CM_ "AUTOGENERATED FILE, DO NOT EDIT";

CM_ "Imported file _subaru_global.dbc starts here";
VERSION ""

NS_ :

BS_:

BU_: XXX X

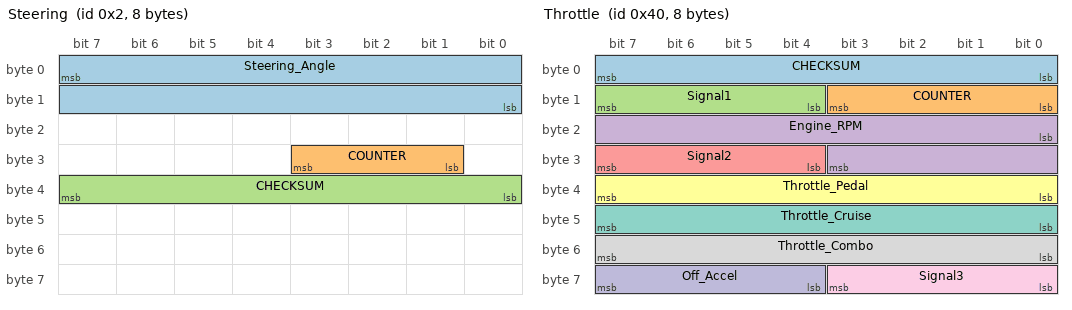
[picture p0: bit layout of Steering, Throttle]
BO_ 2 Steering: 8 XXX
 SG_ Steering_Angle : 7|16@0- (0.1,0) [0|65535] "" XXX
 SG_ COUNTER : 25|3@1+ (1,0) [0|7] "" XXX
 SG_ CHECKSUM : 32|8@1+ (1,0) [0|255] "" XXX

BO_ 64 Throttle: 8 XXX
 SG_ CHECKSUM : 0|8@1+ (1,0) [0|255] "" XXX
 SG_ COUNTER : 8|4@1+ (1,0) [0|15] "" XXX
 SG_ Signal1 : 12|4@1+ (1,0) [0|15] "" XXX
 SG_ Engine_RPM : 16|12@1+ (1,0) [0|4095] "" XXX
 SG_ Signal2 : 28|4@1+ (1,0) [0|15] "" XXX
 SG_ Throttle_Pedal : 32|8@1+ (1,0) [0|255] "" XXX
 SG_ Throttle_Cruise : 40|8@1+ (1,0) [0|255] "" XXX
 SG_ Throttle_Combo : 48|8@1+ (1,0) [0|255] "" XXX
 SG_ Signal3 : 56|4@1+ (1,0) [0|15] "" XXX
 SG_ Off_Accel : 60|4@1+ (1,0) [0|15] "" XXX

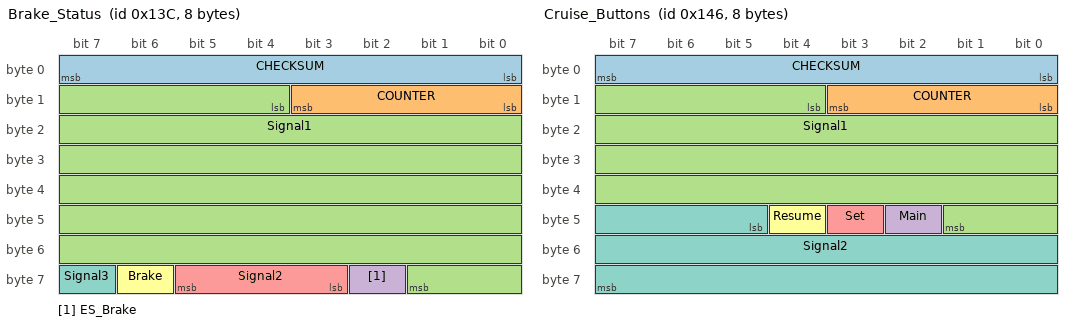
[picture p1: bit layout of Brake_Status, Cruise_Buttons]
BO_ 316 Brake_Status: 8 XXX
 SG_ CHECKSUM : 0|8@1+ (1,0) [0|255] "" XXX
 SG_ COUNTER : 8|4@1+ (1,0) [0|15] "" XXX
 SG_ Signal1 : 12|46@1+ (1,0) [0|1] "" XXX
 SG_ ES_Brake : 58|1@1+ (1,0) [0|1] "" XXX
 SG_ Signal2 : 59|3@1+ (1,0) [0|1] "" XXX
 SG_ Brake : 62|1@1+ (1,0) [0|1] "" XXX
 SG_ Signal3 : 63|1@1+ (1,0) [0|1] "" XXX

BO_ 326 Cruise_Buttons: 8 XXX
 SG_ CHECKSUM : 0|8@1+ (1,0) [0|255] "" XXX
 SG_ COUNTER : 8|4@1+ (1,0) [0|15] "" XXX
 SG_ Signal1 : 12|30@1+ (1,0) [0|1073741823] "" XXX
 SG_ Main : 42|1@1+ (1,0) [0|1] "" XXX
 SG_ Set : 43|1@1+ (1,0) [0|1] "" XXX
 SG_ Resume : 44|1@1+ (1,0) [0|1] "" XXX
 SG_ Signal2 : 45|19@1+ (1,0) [0|524287] "" XXX

BO_ 315 G_Sensor: 8 XXX
 SG_ Lateral : 48|8@1- (-0.1,0) [0|255] "m/s2" XXX
 SG_ Longitudinal : 56|8@1- (-0.1,0) [0|255] "m/s2" XXX

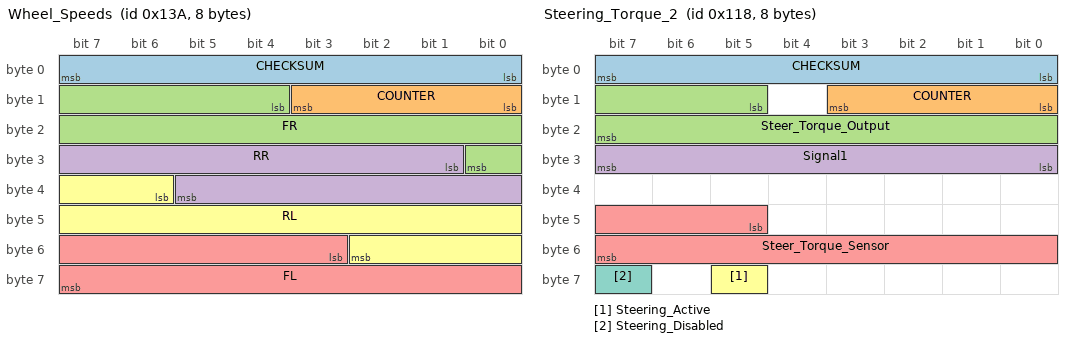
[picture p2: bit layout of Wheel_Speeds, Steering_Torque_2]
BO_ 314 Wheel_Speeds: 8 XXX
 SG_ CHECKSUM : 0|8@1+ (1,0) [0|255] "" XXX
 SG_ COUNTER : 8|4@1+ (1,0) [0|15] "" XXX
 SG_ FR : 12|13@1+ (0.057,0) [0|255] "kph" XXX
 SG_ RR : 25|13@1+ (0.057,0) [0|255] "kph" XXX
 SG_ FL : 51|13@1+ (0.057,0) [0|255] "kph" XXX
 SG_ RL : 38|13@1+ (0.057,0) [0|255] "kph" XXX

BO_ 280 Steering_Torque_2: 8 XXX
 SG_ CHECKSUM : 0|8@1+ (1,0) [0|255] "" XXX
 SG_ COUNTER : 8|4@1+ (1,0) [0|15] "" XXX
 SG_ Steer_Torque_Output : 13|11@1- (-10,0) [0|255] "" XXX
 SG_ Signal1 : 24|8@1+ (1,0) [0|511] "" XXX
 SG_ Steer_Torque_Sensor : 45|11@1- (-1,0) [0|255] "" XXX
 SG_ Steering_Active : 61|1@0+ (1,0) [0|1] "" XXX
 SG_ Steering_Disabled : 63|1@1+ (1,0) [0|1] "" XXX

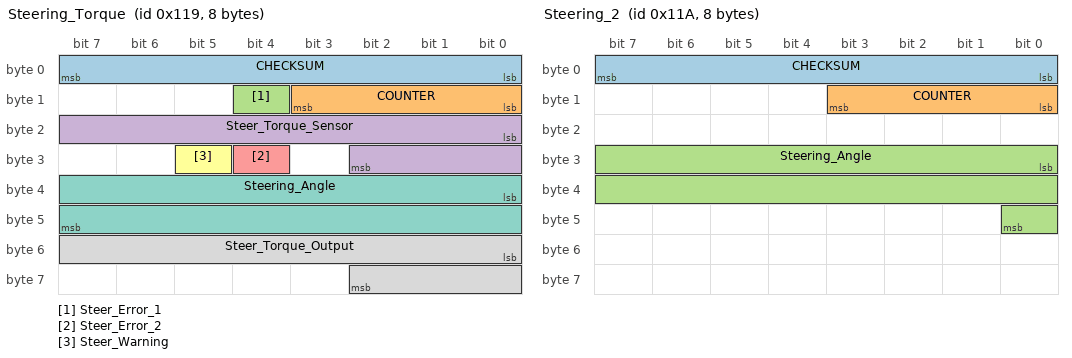
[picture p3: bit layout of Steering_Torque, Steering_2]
BO_ 281 Steering_Torque: 8 XXX
 SG_ CHECKSUM : 0|8@1+ (1,0) [0|255] "" XXX
 SG_ COUNTER : 8|4@1+ (1,0) [0|15] "" XXX
 SG_ Steer_Error_1 : 12|1@0+ (1,0) [0|1] "" XXX
 SG_ Steer_Torque_Sensor : 16|11@1- (-1,0) [-1000|1000] "" XXX
 SG_ Steer_Error_2 : 28|1@1+ (1,0) [0|1] "" XXX
 SG_ Steer_Warning : 29|1@1+ (1,0) [0|1] "" XXX
 SG_ Steering_Angle : 32|16@1- (-0.0217,0) [-600|600] "" X
 SG_ Steer_Torque_Output : 48|11@1- (-10,0) [-1000|1000] "" XXX

BO_ 282 Steering_2: 8 XXX
 SG_ CHECKSUM : 0|8@1+ (1,0) [0|1] "" XXX
 SG_ COUNTER : 8|4@1+ (1,0) [0|1] "" XXX
 SG_ Steering_Angle : 24|17@1- (-0.01,0) [0|1] "" XXX

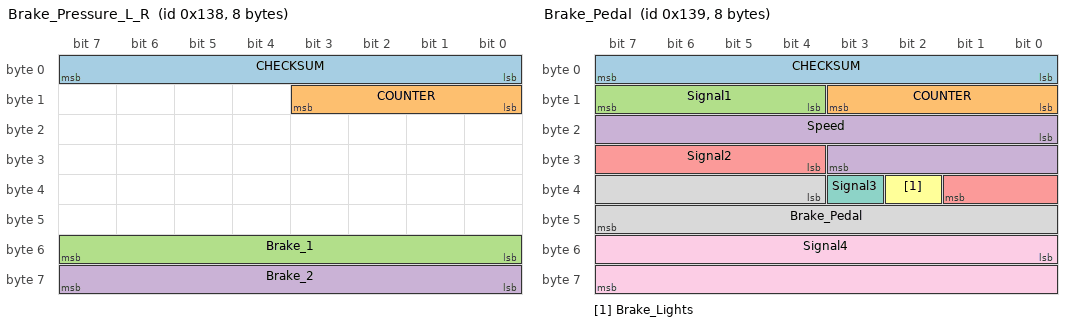
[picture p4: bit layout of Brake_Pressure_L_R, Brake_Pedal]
BO_ 312 Brake_Pressure_L_R: 8 XXX
 SG_ CHECKSUM : 0|8@1+ (1,0) [0|255] "" XXX
 SG_ COUNTER : 8|4@1+ (1,0) [0|15] "" XXX
 SG_ Brake_1 : 48|8@1+ (1,0) [0|255] "" XXX
 SG_ Brake_2 : 56|8@1+ (1,0) [0|255] "" XXX

BO_ 313 Brake_Pedal: 8 XXX
 SG_ CHECKSUM : 0|8@1+ (1,0) [0|255] "" XXX
 SG_ COUNTER : 8|4@1+ (1,0) [0|15] "" XXX
 SG_ Signal1 : 12|4@1+ (1,0) [0|15] "" XXX
 SG_ Speed : 16|12@1+ (0.05625,0) [0|255] "kph" XXX
 SG_ Signal2 : 28|6@1+ (1,0) [0|63] "" XXX
 SG_ Brake_Lights : 34|1@1+ (1,0) [0|1] "" XXX
 SG_ Signal3 : 35|1@1+ (1,0) [0|1] "" XXX
 SG_ Brake_Pedal : 36|12@1+ (1,0) [0|4095] "" XXX
 SG_ Signal4 : 48|16@1+ (1,0) [0|65535] "" XXX

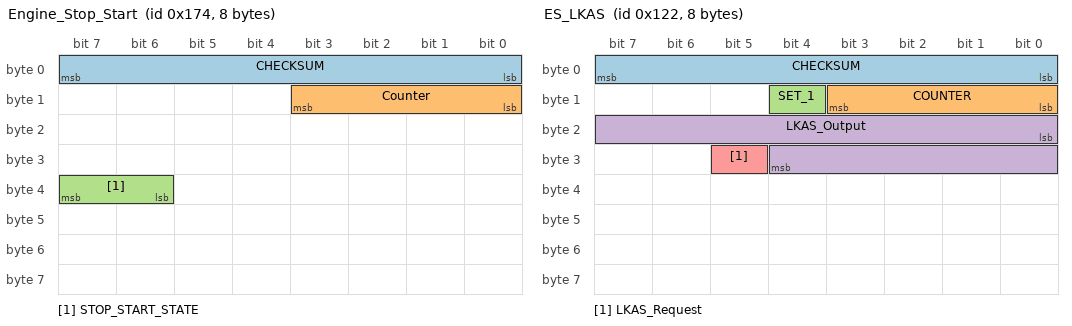
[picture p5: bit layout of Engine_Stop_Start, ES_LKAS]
BO_ 372 Engine_Stop_Start: 8 XXX
 SG_ CHECKSUM : 0|8@1+ (1,0) [0|255] "" XXX
 SG_ Counter : 8|4@1+ (1,0) [0|15] "" XXX
 SG_ STOP_START_STATE : 39|2@0+ (1,0) [0|3] "" XXX

BO_ 290 ES_LKAS: 8 XXX
 SG_ CHECKSUM : 0|8@1+ (1,0) [0|255] "" XXX
 SG_ COUNTER : 8|4@1+ (1,0) [0|15] "" XXX
 SG_ SET_1 : 12|1@0+ (1,0) [0|1] "" XXX
 SG_ LKAS_Output : 16|13@1- (-1,0) [-8191|8191] "" XXX
 SG_ LKAS_Request : 29|1@0+ (1,0) [0|1] "" XXX

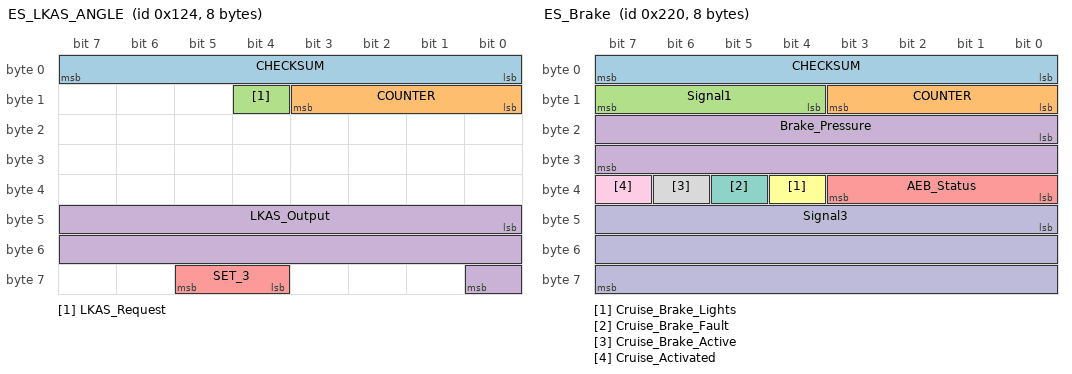
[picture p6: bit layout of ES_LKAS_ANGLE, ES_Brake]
BO_ 292 ES_LKAS_ANGLE: 8 XXX
 SG_ CHECKSUM : 0|8@1+ (1,0) [0|1] "" XXX
 SG_ COUNTER : 8|4@1+ (1,0) [0|1] "" XXX
 SG_ LKAS_Request : 12|1@1+ (1,0) [0|1] "" XXX
 SG_ LKAS_Output : 40|17@1- (-0.01,0) [0|1] "deg" XXX
 SG_ SET_3 : 60|2@1+ (1,0) [0|1] "" XXX

BO_ 544 ES_Brake: 8 XXX
 SG_ CHECKSUM : 0|8@1+ (1,0) [0|255] "" XXX
 SG_ COUNTER : 8|4@1+ (1,0) [0|15] "" XXX
 SG_ Signal1 : 12|4@1+ (1,0) [0|15] "" XXX
 SG_ Brake_Pressure : 16|16@1+ (1,0) [0|65535] "" XXX
 SG_ AEB_Status : 32|4@1+ (1,0) [0|15] "" XXX
 SG_ Cruise_Brake_Lights : 36|1@1+ (1,0) [0|1] "" XXX
 SG_ Cruise_Brake_Fault : 37|1@1+ (1,0) [0|1] "" XXX
 SG_ Cruise_Brake_Active : 38|1@1+ (1,0) [0|1] "" XXX
 SG_ Cruise_Activated : 39|1@1+ (1,0) [0|1] "" XXX
 SG_ Signal3 : 40|24@1+ (1,0) [0|16777215] "" XXX

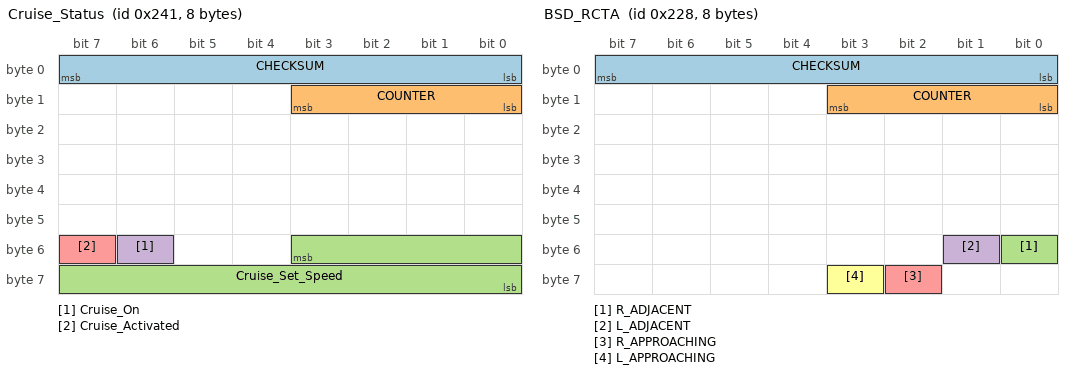
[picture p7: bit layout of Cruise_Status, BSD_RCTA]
BO_ 577 Cruise_Status: 8 XXX
 SG_ CHECKSUM : 0|8@1+ (1,0) [0|255] "" XXX
 SG_ COUNTER : 8|4@1+ (1,0) [0|15] "" XXX
 SG_ Cruise_Set_Speed : 51|12@0+ (1,0) [0|120] "" XXX
 SG_ Cruise_On : 54|1@1+ (1,0) [0|1] "" XXX
 SG_ Cruise_Activated : 55|1@1+ (1,0) [0|1] "" XXX

BO_ 552 BSD_RCTA: 8 XXX
 SG_ CHECKSUM : 0|8@1+ (1,0) [0|255] "" XXX
 SG_ COUNTER : 8|4@1+ (1,0) [0|15] "" XXX
 SG_ R_ADJACENT : 48|1@1+ (1,0) [0|1] "" XXX
 SG_ L_ADJACENT : 49|1@1+ (1,0) [0|1] "" XXX
 SG_ R_APPROACHING : 58|1@1+ (1,0) [0|1] "" XXX
 SG_ L_APPROACHING : 59|1@1+ (1,0) [0|1] "" XXX

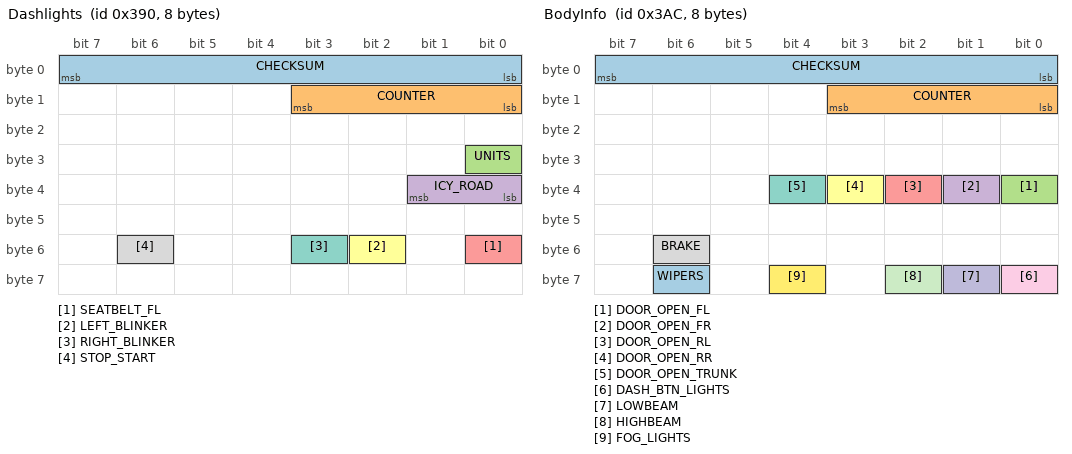
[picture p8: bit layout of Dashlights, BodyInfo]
BO_ 912 Dashlights: 8 XXX
 SG_ CHECKSUM : 0|8@1+ (1,0) [0|255] "" XXX
 SG_ COUNTER : 8|4@1+ (1,0) [0|15] "" XXX
 SG_ UNITS : 24|1@1+ (1,0) [0|1] "" XXX
 SG_ ICY_ROAD : 32|2@1+ (1,0) [0|3] "" XXX
 SG_ SEATBELT_FL : 48|1@1+ (1,0) [0|1] "" XXX
 SG_ LEFT_BLINKER : 50|1@1+ (1,0) [0|1] "" XXX
 SG_ RIGHT_BLINKER : 51|1@1+ (1,0) [0|1] "" XXX
 SG_ STOP_START : 54|1@0+ (1,0) [0|1] "" XXX

BO_ 940 BodyInfo: 8 XXX
 SG_ CHECKSUM : 0|8@1+ (1,0) [0|255] "" XXX
 SG_ COUNTER : 8|4@1+ (1,0) [0|15] "" XXX
 SG_ DOOR_OPEN_FL : 32|1@1+ (1,0) [0|1] "" XXX
 SG_ DOOR_OPEN_FR : 33|1@1+ (1,0) [0|1] "" XXX
 SG_ DOOR_OPEN_RL : 34|1@1+ (1,0) [0|1] "" XXX
 SG_ DOOR_OPEN_RR : 35|1@1+ (1,0) [0|1] "" XXX
 SG_ DOOR_OPEN_TRUNK : 36|1@0+ (1,0) [0|1] "" XXX
 SG_ BRAKE : 54|1@1+ (1,0) [0|1] "" XXX
 SG_ DASH_BTN_LIGHTS : 56|1@0+ (1,0) [0|1] "" XXX
 SG_ LOWBEAM : 57|1@1+ (1,0) [0|1] "" XXX
 SG_ HIGHBEAM : 58|1@1+ (1,0) [0|1] "" XXX
 SG_ FOG_LIGHTS : 60|1@1+ (1,0) [0|1] "" XXX
 SG_ WIPERS : 62|1@0+ (1,0) [0|1] "" XXX

BO_ 801 ES_DashStatus: 8 XXX
 SG_ CHECKSUM : 0|8@1+ (1,0) [0|255] "" XXX
 SG_ COUNTER : 8|4@1+ (1,0) [0|15] "" XXX
 SG_ PCB_Off : 12|1@1+ (1,0) [0|1] "" XXX
 SG_ LDW_Off : 13|1@1+ (1,0) [0|1] "" XXX
 SG_ Signal1 : 14|2@1+ (1,0) [0|3] "" XXX
 SG_ Cruise_State_Msg : 16|4@1+ (1,0) [0|15] "" XXX
 SG_ LKAS_State_Msg : 20|3@1+ (1,0) [0|7] "" XXX
 SG_ Signal2 : 23|1@1+ (1,0) [0|1] "" XXX
 SG_ Cruise_Soft_Disable : 24|1@1+ (1,0) [0|1] "" XXX
 SG_ Cruise_Status_Msg : 25|2@1+ (1,0) [0|3] "" XXX
 SG_ Signal3 : 27|1@1+ (1,0) [0|1] "" XXX
 SG_ Cruise_Distance : 28|3@1+ (1,0) [0|7] "" XXX
 SG_ Signal4 : 31|1@1+ (1,0) [0|1] "" XXX
 SG_ Conventional_Cruise : 32|1@1+ (1,0) [0|1] "" XXX
 SG_ Signal5 : 33|2@1+ (1,0) [0|3] "" XXX
 SG_ Cruise_Disengaged : 35|1@1+ (1,0) [0|1] "" XXX
 SG_ Cruise_Activated : 36|1@1+ (1,0) [0|1] "" XXX
 SG_ Signal6 : 37|3@1+ (1,0) [0|1] "" XXX
 SG_ Cruise_Set_Speed : 40|8@1+ (1,0) [0|255] "" XXX
 SG_ Cruise_Fault : 48|1@1+ (1,0) [0|1] "" XXX
 SG_ Cruise_On : 49|1@1+ (1,0) [0|1] "" XXX
 SG_ Display_Own_Car : 50|1@1+ (1,0) [0|1] "" XXX
 SG_ Brake_Lights : 51|1@1+ (1,0) [0|1] "" XXX
 SG_ Car_Follow : 52|1@1+ (1,0) [0|1] "" XXX
 SG_ Signal7 : 53|3@1+ (1,0) [0|1] "" XXX
 SG_ Far_Distance : 56|4@1+ (5,0) [0|75] "m" XXX
 SG_ Cruise_State : 60|4@1+ (1,0) [0|15] "" XXX

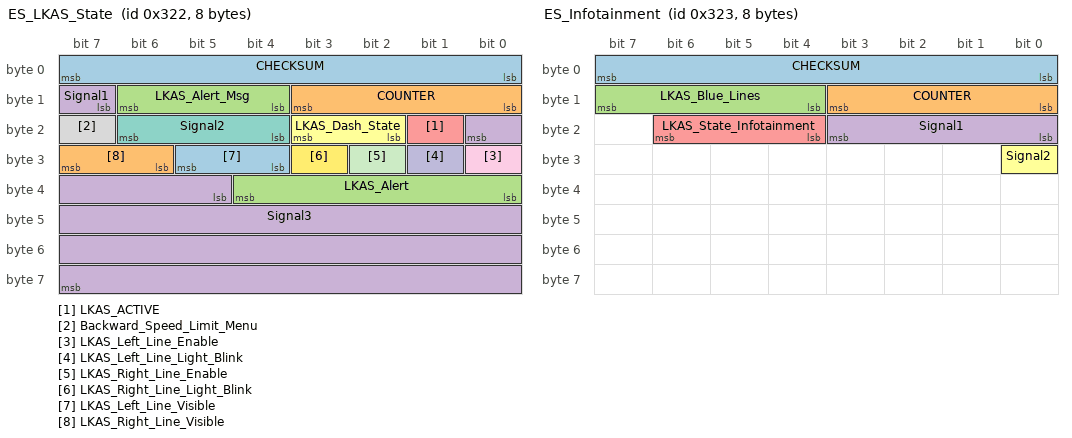
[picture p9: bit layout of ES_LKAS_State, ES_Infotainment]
BO_ 802 ES_LKAS_State: 8 XXX
 SG_ CHECKSUM : 0|8@1+ (1,0) [0|255] "" XXX
 SG_ COUNTER : 8|4@1+ (1,0) [0|15] "" XXX
 SG_ LKAS_Alert_Msg : 12|3@1+ (1,0) [0|7] "" XXX
 SG_ Signal1 : 15|2@1+ (1,0) [0|3] "" XXX
 SG_ LKAS_ACTIVE : 17|1@1+ (1,0) [0|1] "" XXX
 SG_ LKAS_Dash_State : 18|2@1+ (1,0) [0|2] "" XXX
 SG_ Signal2 : 20|3@1+ (1,0) [0|7] "" XXX
 SG_ Backward_Speed_Limit_Menu : 23|1@1+ (1,0) [0|1] "" XXX
 SG_ LKAS_Left_Line_Enable : 24|1@1+ (1,0) [0|1] "" XXX
 SG_ LKAS_Left_Line_Light_Blink : 25|1@1+ (1,0) [0|1] "" XXX
 SG_ LKAS_Right_Line_Enable : 26|1@1+ (1,0) [0|1] "" XXX
 SG_ LKAS_Right_Line_Light_Blink : 27|1@1+ (1,0) [0|1] "" XXX
 SG_ LKAS_Left_Line_Visible : 28|2@1+ (1,0) [0|3] "" XXX
 SG_ LKAS_Right_Line_Visible : 30|2@1+ (1,0) [0|3] "" XXX
 SG_ LKAS_Alert : 32|5@1+ (1,0) [0|31] "" XXX
 SG_ Signal3 : 37|27@1+ (1,0) [0|1] "" XXX

BO_ 803 ES_Infotainment: 8 XXX
 SG_ CHECKSUM : 0|8@1+ (1,0) [0|255] "" XXX
 SG_ COUNTER : 8|4@1+ (1,0) [0|15] "" XXX
 SG_ LKAS_Blue_Lines : 15|4@0+ (1,0) [0|15] "" XXX
 SG_ Signal1 : 19|4@0+ (1,0) [0|15] "" XXX
 SG_ LKAS_State_Infotainment : 22|3@0+ (1,0) [0|7] "" XXX
 SG_ Signal2 : 24|1@0+ (1,0) [0|1] "" XXX

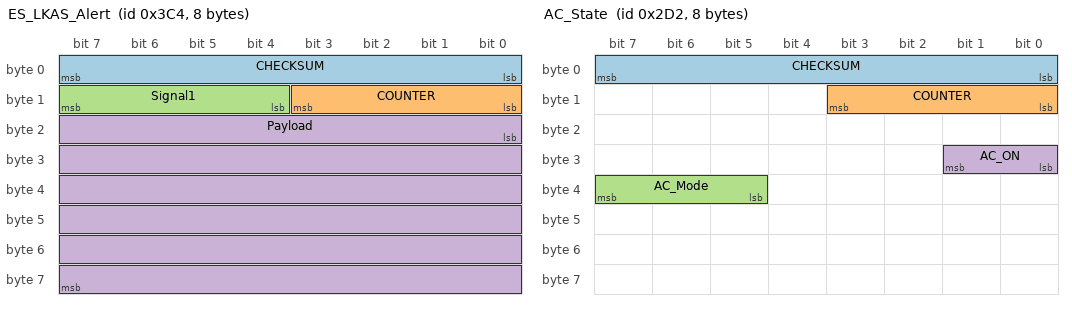
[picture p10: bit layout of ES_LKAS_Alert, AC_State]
BO_ 964 ES_LKAS_Alert: 8 XXX
 SG_ CHECKSUM : 0|8@1+ (1,0) [0|255] "" XXX
 SG_ COUNTER : 8|4@1+ (1,0) [0|15] "" XXX
 SG_ Signal1 : 12|4@1+ (1,0) [0|15] "" XXX
 SG_ Payload : 16|48@1+ (1,0) [0|281474976710655] "" XXX

BO_ 722 AC_State: 8 XXX
 SG_ CHECKSUM : 0|8@1+ (1,0) [0|255] "" XXX
 SG_ COUNTER : 8|4@1+ (1,0) [0|15] "" XXX
 SG_ AC_Mode : 37|3@1+ (1,0) [0|1] "" XXX
 SG_ AC_ON : 24|2@1+ (1,0) [0|1] "" XXX

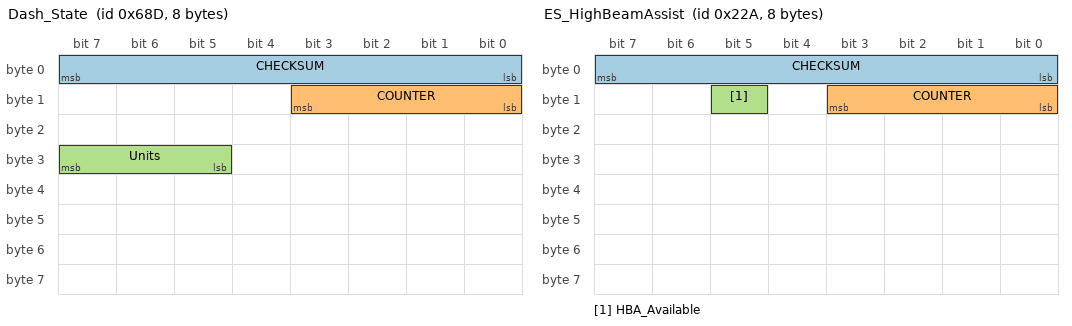
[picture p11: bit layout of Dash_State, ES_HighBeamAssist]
BO_ 1677 Dash_State: 8 XXX
 SG_ CHECKSUM : 0|8@1+ (1,0) [0|255] "" XXX
 SG_ COUNTER : 8|4@1+ (1,0) [0|15] "" XXX
 SG_ Units : 29|3@1+ (1,0) [0|7] "" XXX

BO_ 554 ES_HighBeamAssist: 8 XXX
 SG_ CHECKSUM : 0|8@1+ (1,0) [0|255] "" XXX
 SG_ COUNTER : 8|4@1+ (1,0) [0|15] "" XXX
 SG_ HBA_Available : 13|1@0+ (1,0) [0|1] "" XXX

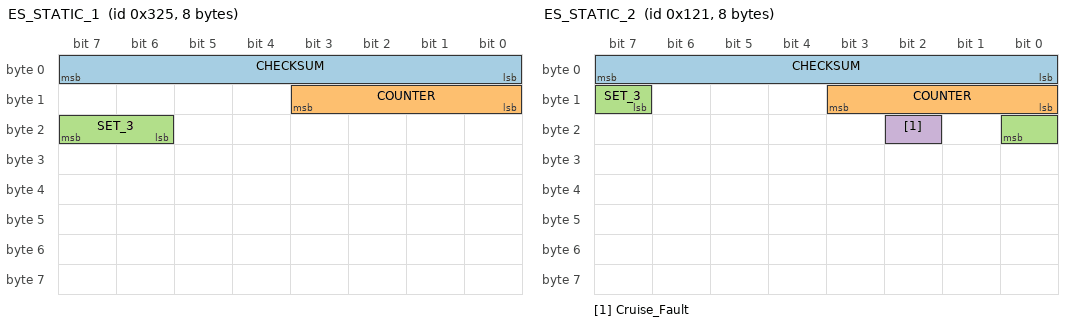
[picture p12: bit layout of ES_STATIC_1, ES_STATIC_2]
BO_ 805 ES_STATIC_1: 8 XXX
 SG_ CHECKSUM : 0|8@1+ (1,0) [0|255] "" XXX
 SG_ COUNTER : 8|4@1+ (1,0) [0|15] "" XXX
 SG_ SET_3 : 23|2@0+ (1,0) [0|3] "" XXX

BO_ 289 ES_STATIC_2: 8 XXX
 SG_ CHECKSUM : 0|8@1+ (1,0) [0|255] "" XXX
 SG_ COUNTER : 8|4@1+ (1,0) [0|15] "" XXX
 SG_ SET_3 : 15|2@1+ (1,0) [0|3] "" XXX
 SG_ Cruise_Fault : 18|1@0+ (1,0) [0|1] "" XXX

CM_ SG_ 64 Throttle_Combo "Throttle Cruise + Pedal";
CM_ SG_ 313 Brake_Lights "Driver or Cruise Brake on";
CM_ SG_ 544 Cruise_Brake_Lights "1 = switch on brake lights";
CM_ SG_ 544 Brake_Pressure "Winds down after cruise disabled. Also can be non-zero when likely preparing for AEB";
CM_ SG_ 544 Signal3 "Usually goes to 2 if AEB_Status is 4";
CM_ SG_ 544 AEB_Status "Occasionally is 4 instead of 8 while Brake_Pressure is non-zero, unsure why";
CM_ SG_ 801 PCB_Off "Pre-Collision Braking off";
CM_ SG_ 801 Brake_Lights "Driver or Cruise brake on";
CM_ SG_ 801 Cruise_State "0 = Normal, 1 = Hold+User Brake, 2 = Ready, 3 = Hold";
CM_ SG_ 801 Far_Distance "1=0-5m, 2=5-10m, 3=10-15m, 4=15-20m, 5=20-25m, 6=25-30m, 7=30-35m, 8=35-40m, 9=40-45m, 10=45-50m, 11=50-55m, 12=55-60m, 13=60-65m, 14=65-70m, 15=75m+";
CM_ SG_ 801 LKAS_State_Msg "1 = LKAS_Off_Sharp_Curve, 2 = Keep_Hands_On_Steering_wheel_disabled, 3 = LKAS_Off, 4 = LKAS_Off_Too_Slow, 5 = LKAS_Off_Too_Fast";
CM_ SG_ 801 Cruise_State_Msg "1 = Cruise_Off_Steep_Slope, 2 = Cruise_lvl1_eco, 3 = Cruise_lvl2_comfort, 4 = Cruise_off_empty_reason, 5 = Cruise_off, 6 = Cruise_Unable_to_set, 7 = Cruise_Unable_to_set_brakes_applied, 8 = Eyesight_not_ready, 9 = Cruise_lvl3_standard, 10 = Cruise_lvl4_dynamic, 11 = Cruise_Unable_to_set_steep_slope";
CM_ SG_ 801 Cruise_Soft_Disable "Eyesight soft disable (eg direct sunlight)";
CM_ SG_ 801 Cruise_Status_Msg "1 = Disabled_Bad_Visibility, 2 = Disabled_Check_Manual";
CM_ SG_ 802 LKAS_ACTIVE "Turns on the full LKAS dash display";
CM_ SG_ 802 LKAS_Alert_Msg "1 = Keep_Hands_On_Wheel, 6 = Pre_Collision_Braking, 7 = Keep_Hands_On_Wheel_Off";
CM_ SG_ 802 LKAS_Alert "1 = FCW_Cont_Beep, 2 = FCW_Repeated_Beep, 3 = Throttle_Management_Activated_Warning, 4 = Throttle_Management_Activated_Alert, 5 = Pre_Collision_Activated_Alert, 8 = Traffic_Light_Ahead, 9 = Apply_Brake_to_Hold Position, 11 = LDW_Right, 12 = LDW_Left, 13 = Stay_Alert, 14 = Lead_Vehicle_Start_Alert, 18 = Keep_Hands_On_Steering_Alert, 24 = Audio_Beep, 25 = Audio_Lead_Car_Change, 26 = Audio_ACC_Disengaged, 27 = Audio_LKAS_disabled, 28 = Audio_Ding_Ding, 30 = Audio_Repeated_Beep";
CM_ SG_ 802 LKAS_Left_Line_Visible "0 = Off, 1 = White, 2 = Green, 3 = Orange";
CM_ SG_ 802 LKAS_Dash_State "0 = Off, 1 = Ready, 2 = Active";
CM_ SG_ 802 LKAS_Right_Line_Visible "0 = Off, 1 = White, 2 = Green, 3 = Orange";
CM_ SG_ 912 UNITS "0 = Metric, 1 = Imperial";
CM_ SG_ 912 ICY_ROAD "1 = DASHLIGHT ON, 2 = WARNING, 3 = OFF";
VAL_ 544 AEB_Status 12 "AEB related" 8 "AEB actuation" 4 "AEB related" 0 "No AEB actuation";

CM_ "subaru_global_2017.dbc starts here";

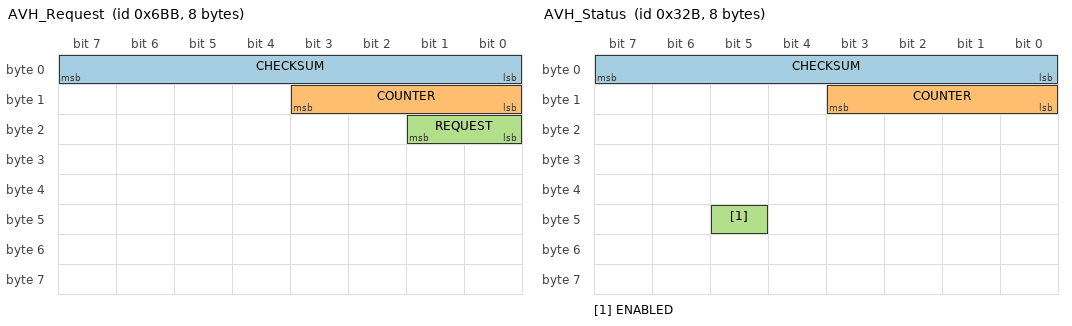
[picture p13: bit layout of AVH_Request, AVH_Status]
BO_ 1723 AVH_Request: 8 XXX
 SG_ CHECKSUM : 0|8@1+ (1,0) [0|255] "" XXX
 SG_ COUNTER : 8|4@1+ (1,0) [0|15] "" XXX
 SG_ REQUEST : 16|2@1+ (1,0) [0|3] "" XXX

BO_ 811 AVH_Status: 8 XXX
 SG_ CHECKSUM : 0|8@1+ (1,0) [0|255] "" XXX
 SG_ COUNTER : 8|4@1+ (1,0) [0|15] "" XXX
 SG_ ENABLED : 45|1@1+ (1,0) [0|1] "" XXX

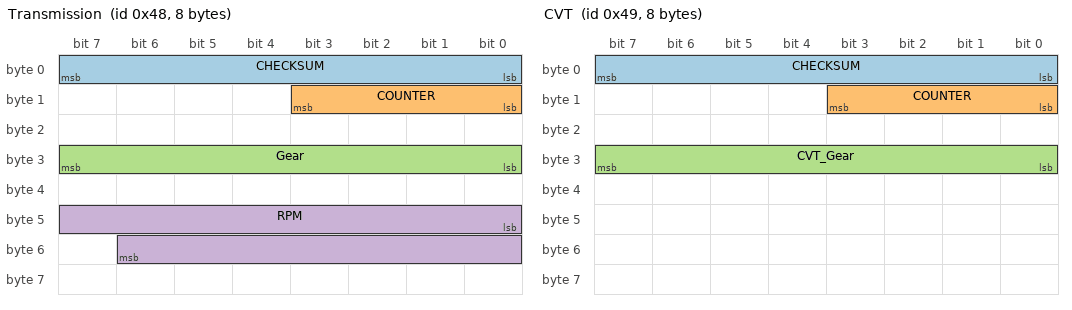
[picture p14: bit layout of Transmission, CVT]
BO_ 72 Transmission: 8 XXX
 SG_ CHECKSUM : 0|8@1+ (1,0) [0|255] "" XXX
 SG_ COUNTER : 8|4@1+ (1,0) [0|15] "" XXX
 SG_ Gear : 24|8@1+ (1,0) [0|255] "" XXX
 SG_ RPM : 40|15@1+ (1,0) [0|65535] "" XXX

BO_ 73 CVT: 8 XXX
 SG_ CHECKSUM : 0|8@1+ (1,0) [0|255] "" XXX
 SG_ COUNTER : 8|4@1+ (1,0) [0|15] "" XXX
 SG_ CVT_Gear : 24|8@1+ (1,0) [0|255] "" XXX

BO_ 545 ES_Distance: 8 XXX
 SG_ CHECKSUM : 0|8@1+ (1,0) [0|255] "" XXX
 SG_ COUNTER : 8|4@1+ (1,0) [0|15] "" XXX
 SG_ Signal1 : 12|3@1+ (1,0) [0|7] "" XXX
 SG_ Cruise_Fault : 15|1@1+ (1,0) [0|1] "" XXX
 SG_ Cruise_Throttle : 16|13@1+ (1,0) [0|4095] "" XXX
 SG_ Signal2 : 29|3@1+ (1,0) [0|15] "" XXX
 SG_ Car_Follow : 32|1@1+ (1,0) [0|1] "" XXX
 SG_ Low_Speed_Follow : 33|1@1+ (1,0) [0|1] "" XXX
 SG_ Cruise_Soft_Disable : 34|1@1+ (1,0) [0|1] "" XXX
 SG_ Signal7 : 35|1@1+ (1,0) [0|1] "" XXX
 SG_ Cruise_Brake_Active : 36|1@1+ (1,0) [0|1] "" XXX
 SG_ Distance_Swap : 37|1@1+ (1,0) [0|1] "" XXX
 SG_ Cruise_EPB : 38|1@1+ (1,0) [0|1] "" XXX
 SG_ Signal4 : 39|1@0+ (1,0) [0|1] "" XXX
 SG_ Close_Distance : 40|8@1+ (0.019607,0) [0|5] "m" XXX
 SG_ Signal5 : 48|8@1+ (1,0) [0|1] "" XXX
 SG_ Cruise_Cancel : 56|1@1+ (1,0) [0|1] "" XXX
 SG_ Cruise_Set : 57|1@1+ (1,0) [0|1] "" XXX
 SG_ Cruise_Resume : 58|1@1+ (1,0) [0|1] "" XXX
 SG_ Signal6 : 59|5@1+ (1,0) [0|1] "" XXX

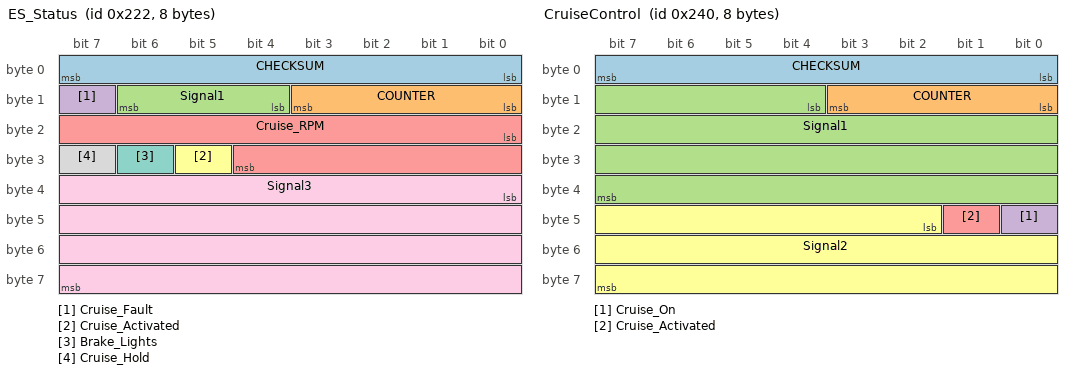
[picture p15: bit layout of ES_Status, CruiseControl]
BO_ 546 ES_Status: 8 XXX
 SG_ CHECKSUM : 0|8@1+ (1,0) [0|255] "" XXX
 SG_ COUNTER : 8|4@1+ (1,0) [0|15] "" XXX
 SG_ Signal1 : 12|3@1+ (1,0) [0|1] "" XXX
 SG_ Cruise_Fault : 15|1@1+ (1,0) [0|1] "" XXX
 SG_ Cruise_RPM : 16|13@1+ (1,0) [0|4095] "" XXX
 SG_ Cruise_Activated : 29|1@0+ (1,0) [0|1] "" XXX
 SG_ Brake_Lights : 30|1@1+ (1,0) [0|1] "" XXX
 SG_ Cruise_Hold : 31|1@1+ (1,0) [0|1] "" XXX
 SG_ Signal3 : 32|32@1+ (1,0) [0|1] "" XXX

BO_ 576 CruiseControl: 8 XXX
 SG_ CHECKSUM : 0|8@1+ (1,0) [0|255] "" XXX
 SG_ COUNTER : 8|4@1+ (1,0) [0|15] "" XXX
 SG_ Signal1 : 12|28@1+ (1,0) [0|268435455] "" XXX
 SG_ Cruise_On : 40|1@1+ (1,0) [0|1] "" XXX
 SG_ Cruise_Activated : 41|1@1+ (1,0) [0|1] "" XXX
 SG_ Signal2 : 42|22@1+ (1,0) [0|4194303] "" XXX

CM_ SG_ 545 Cruise_Throttle "RPM-like output signal";
CM_ SG_ 545 Cruise_EPB "1 = Electric Parking Brake set";
CM_ SG_ 545 Distance_Swap "Switch from Close to Far distance";
CM_ SG_ 545 Cruise_Soft_Disable "Eyesight Temporary disable, sets CruiseControl Activated = 0";
CM_ SG_ 546 Cruise_RPM "ES RPM output for ECM and TCM";
CM_ SG_ 546 Signal3 "0 when cruise_activated = 1";
CM_ SG_ 803 Signal1 "Seems to be static, set only on some cars";
CM_ SG_ 803 Signal2 "Seems to be static, set only on some cars";
VAL_ 803 LKAS_Blue_Lines 0 "no modifier" 2 "changes lines to blue";
VAL_ 803 LKAS_State_Infotainment 0 "none" 2 "Obstacle Detected" 3 "Keep Hands On Wheel" 4 "Keep Hands On Wheel Off";
VAL_ 72 Gear 2 "N" 3 "R" 4 "P" 121 "D" 137 "1" 145 "2" 153 "3" 161 "4" 169 "5" 177 "6";
